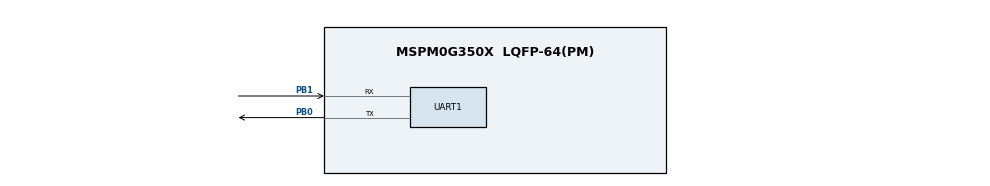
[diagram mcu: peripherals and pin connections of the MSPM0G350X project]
/**
 * @cliArgs --device "MSPM0G350X" --part "Default" --package "LQFP-64(PM)" --product "mspm0_sdk@2.09.00.00"
 * @versions {"tool":"1.25.0+4268"}
 */

/**
 * Import the modules used in this configuration.
 */
const ADC12         = scripting.addModule("/ti/driverlib/ADC12", {}, false);
const ADC121        = ADC12.addInstance();
const CAPTURE       = scripting.addModule("/ti/driverlib/CAPTURE", {}, false);
const CAPTURE1      = CAPTURE.addInstance();
const COMP          = scripting.addModule("/ti/driverlib/COMP", {}, false);
const COMP1         = COMP.addInstance();
const DAC12         = scripting.addModule("/ti/driverlib/DAC12");
const GPIO          = scripting.addModule("/ti/driverlib/GPIO", {}, false);
const GPIO1         = GPIO.addInstance();
const SYSCTL        = scripting.addModule("/ti/driverlib/SYSCTL");
const TIMER         = scripting.addModule("/ti/driverlib/TIMER", {}, false);
const TIMER1        = TIMER.addInstance();
const UART          = scripting.addModule("/ti/driverlib/UART", {}, false);
const UART1         = UART.addInstance();
const ProjectConfig = scripting.addModule("/ti/project_config/ProjectConfig");

/**
 * Write custom configuration values to the imported modules.
 */
const divider2       = system.clockTree["HFCLK4MFPCLKDIV"];
divider2.divideValue = 2;

const divider6       = system.clockTree["PLL_CLK2X_DIV"];
divider6.divideValue = 4;

const divider7       = system.clockTree["PLL_PDIV"];
divider7.divideValue = 2;

const divider9       = system.clockTree["UDIV"];
divider9.divideValue = 2;

const gate8  = system.clockTree["MFPCLKGATE"];
gate8.enable = true;

const multiplier2         = system.clockTree["PLL_QDIV"];
multiplier2.multiplyValue = 10;

const mux2       = system.clockTree["CANCLKMUX"];
mux2.inputSelect = "CANCLKMUX_PLLCLK1_OUT";

const mux4       = system.clockTree["EXHFMUX"];
mux4.inputSelect = "EXHFMUX_XTAL";

const mux8       = system.clockTree["HSCLKMUX"];
mux8.inputSelect = "HSCLKMUX_SYSPLL2X";

const pinFunction4     = system.clockTree["HFXT"];
pinFunction4.inputFreq = 8;

ADC121.$name                             = "ADC12_0";
ADC121.trigSrc                           = "DL_ADC12_TRIG_SRC_EVENT";
ADC121.powerDownMode                     = "DL_ADC12_POWER_DOWN_MODE_MANUAL";
ADC121.sampleTime0                       = "62.5ns";
ADC121.configureDMA                      = true;
ADC121.subChanID                         = 2;
ADC121.enabledDMATriggers                = ["DL_ADC12_DMA_MEM0_RESULT_LOADED"];
ADC121.repeatMode                        = true;
ADC121.sampCnt                           = 1;
ADC121.adcMem0trig                       = "DL_ADC12_TRIGGER_MODE_TRIGGER_NEXT";
ADC121.enabledInterrupts                 = ["DL_ADC12_INTERRUPT_DMA_DONE"];
ADC121.peripheral.adcPin0.$assign        = "PA27";
ADC121.adcPin0Config.$name               = "ti_driverlib_gpio_GPIOPinGeneric0";
ADC121.DMA_CHANNEL.srcLength             = "HALF_WORD";
ADC121.DMA_CHANNEL.dstLength             = "HALF_WORD";
ADC121.DMA_CHANNEL.configureTransferSize = true;
ADC121.DMA_CHANNEL.$name                 = "DMA_CH1";
ADC121.DMA_CHANNEL.addressMode           = "f2b";
ADC121.DMA_CHANNEL.transferMode          = "FULL_CH_REPEAT_SINGLE";
ADC121.DMA_CHANNEL.transferSize          = 1024;

const Board = scripting.addModule("/ti/driverlib/Board", {}, false);

CAPTURE1.$name              = "CAPTURE_0";
CAPTURE1.captSelect         = "Trigger";
CAPTURE1.captMode           = "PERIOD_CAPTURE";
CAPTURE1.captEdgeDetection  = "FALLING";
CAPTURE1.subscriberChannel  = 1;
CAPTURE1.subscriberPort     = "FSUB0";
CAPTURE1.interrupts         = ["CC0_DN"];
CAPTURE1.interruptPriority  = "0";
CAPTURE1.timerClkDiv        = 2;
CAPTURE1.timerPeriod        = "1.6384 ms";
CAPTURE1.peripheral.$assign = "TIMA0";

COMP1.$name                          = "COMP_0";
COMP1.pubChanID                      = 1;
COMP1.channelEnable                  = ["POS"];
COMP1.terminalSelect                 = "DL_COMP_REF_TERMINAL_SELECT_NEG";
COMP1.controlSelect                  = "DL_COMP_DAC_CONTROL_SW";
COMP1.enabledEvents                  = ["DL_COMP_EVENT_OUTPUT_EDGE"];
COMP1.vSource                        = "DL_COMP_REF_SOURCE_VDDA_DAC";
COMP1.setDACCode0                    = 0x7F;
COMP1.enableOutputFilter             = true;
COMP1.outputEnable                   = true;
COMP1.hysteresis                     = "DL_COMP_HYSTERESIS_20";
COMP1.compPinPos0Config.$name        = "ti_driverlib_gpio_GPIOPinGeneric1";
COMP1.peripheral.compPinPos0.$assign = "PA26";
COMP1.compPinOutConfig.$name         = "ti_driverlib_gpio_GPIOPinGeneric5";

DAC12.dacAmplifier       = "ON";
DAC12.dacOutputPinEn     = true;
DAC12.OutPinConfig.$name = "ti_driverlib_gpio_GPIOPinGeneric2";

GPIO1.$name                          = "GPIO_LEDS";
GPIO1.associatedPins[0].$name        = "LED1";
GPIO1.associatedPins[0].assignedPort = "PORTA";
GPIO1.associatedPins[0].assignedPin  = "0";
GPIO1.associatedPins[0].initialValue = "SET";

SYSCTL.clockTreeEn     = true;
SYSCTL.MFPCLKEn        = true;
SYSCTL.HFCLK4MFPCLKDIV = "2";

TIMER1.$name                       = "TIMER_0";
TIMER1.timerClkDiv                 = 2;
TIMER1.timerMode                   = "PERIODIC";
TIMER1.event1PublisherChannel      = 2;
TIMER1.event1ControllerInterruptEn = ["ZERO_EVENT"];
TIMER1.timerPeriod                 = "5us";
TIMER1.peripheral.$assign          = "TIMG0";

UART1.$name                          = "UART_0";
UART1.targetBaudRate                 = 115200;
UART1.enableFIFO                     = true;
UART1.enabledDMATXTriggers           = "DL_UART_DMA_INTERRUPT_TX";
UART1.enabledInterrupts              = ["DMA_DONE_TX","EOT_DONE"];
UART1.peripheral.$assign             = "UART0";
UART1.peripheral.rxPin.$assign       = "PB1";
UART1.peripheral.txPin.$assign       = "PB0";
UART1.txPinConfig.$name              = "ti_driverlib_gpio_GPIOPinGeneric3";
UART1.rxPinConfig.$name              = "ti_driverlib_gpio_GPIOPinGeneric4";
UART1.DMA_CHANNEL_TX.$name           = "DMA_CH0";
UART1.DMA_CHANNEL_TX.addressMode     = "b2f";
UART1.DMA_CHANNEL_TX.srcLength       = "BYTE";
UART1.DMA_CHANNEL_TX.dstLength       = "BYTE";
UART1.DMA_CHANNEL_TX.enableInterrupt = true;

ProjectConfig.genLibCMSIS = true;

/**
 * Pinmux solution for unlocked pins/peripherals. This ensures that minor changes to the automatic solver in a future
 * version of the tool will not impact the pinmux you originally saw.  These lines can be completely deleted in order to
 * re-solve from scratch.
 */
ADC121.peripheral.$suggestSolution               = "ADC0";
ADC121.DMA_CHANNEL.peripheral.$suggestSolution   = "DMA_CH1";
Board.peripheral.$suggestSolution                = "DEBUGSS";
Board.peripheral.swclkPin.$suggestSolution       = "PA20";
Board.peripheral.swdioPin.$suggestSolution       = "PA19";
COMP1.peripheral.$suggestSolution                = "COMP0";
COMP1.peripheral.compPinOut.$suggestSolution     = "PA11";
DAC12.peripheral.$suggestSolution                = "DAC0";
DAC12.peripheral.OutPin.$suggestSolution         = "PA15";
GPIO1.associatedPins[0].pin.$suggestSolution     = "PA0";
UART1.DMA_CHANNEL_TX.peripheral.$suggestSolution = "DMA_CH0";
